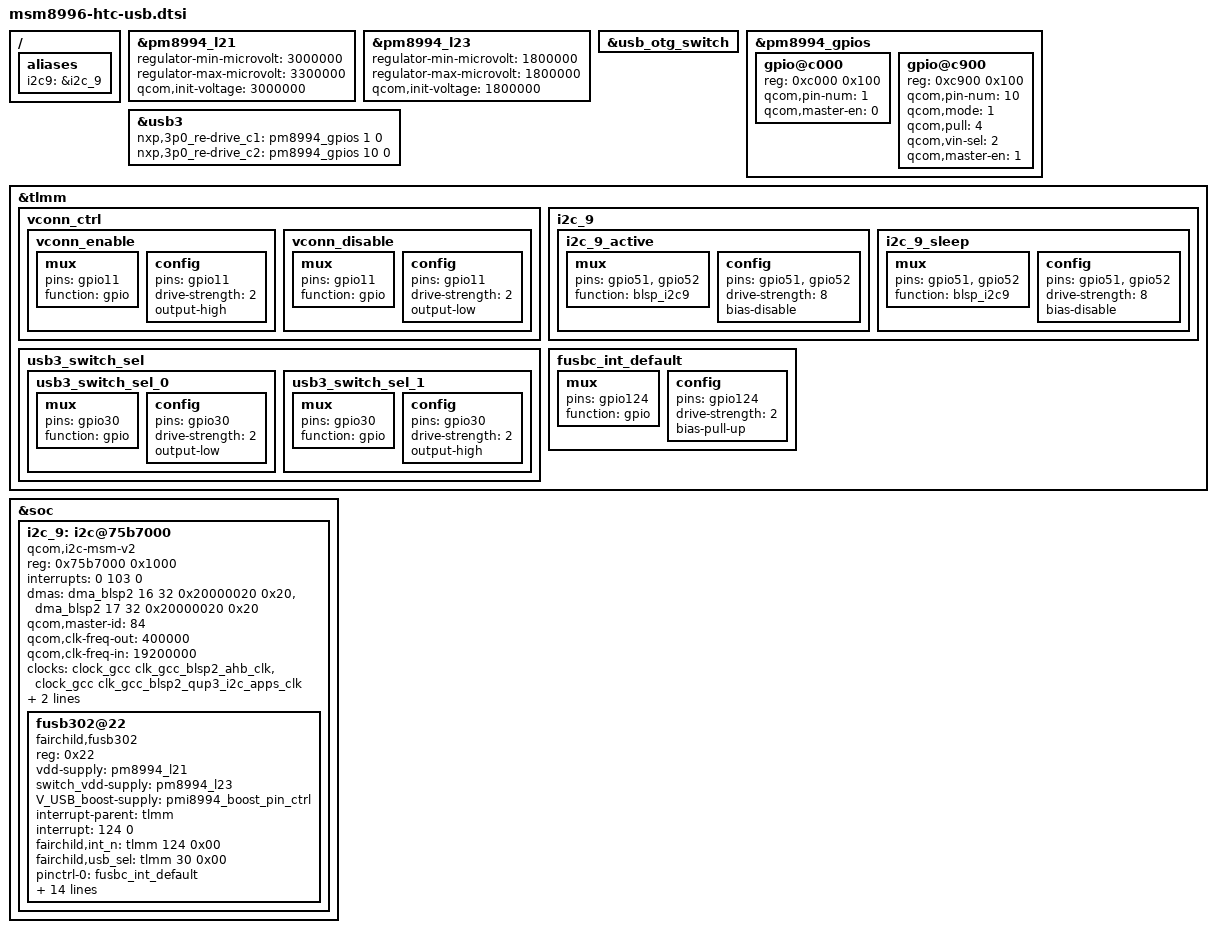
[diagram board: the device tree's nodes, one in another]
/* Copyright (c) 2016, The Linux Foundation. All rights reserved.
 *
 * This program is free software; you can redistribute it and/or modify
 * it under the terms of the GNU General Public License version 2 and
 * only version 2 as published by the Free Software Foundation.
 *
 * This program is distributed in the hope that it will be useful,
 * but WITHOUT ANY WARRANTY; without even the implied warranty of
 * MERCHANTABILITY or FITNESS FOR A PARTICULAR PURPOSE.  See the
 * GNU General Public License for more details.
 */

#include <dt-bindings/usb/typec.h>

&pm8994_l21 {
	regulator-min-microvolt = <3000000>;
	regulator-max-microvolt = <3300000>;
	qcom,init-voltage = <3000000>;
};

&pm8994_l23 {
	regulator-min-microvolt = <1800000>;
	regulator-max-microvolt = <1800000>;
	qcom,init-voltage = <1800000>;
};

&usb_otg_switch {
        status = "okay";
};

&pm8994_gpios {
	gpio@c000 {
		reg = <0xc000 0x100>;
		qcom,pin-num = <1>;
		qcom,master-en = <0>;
		status = "okay";
	};

	gpio@c900 {
		reg = <0xc900 0x100>;
		qcom,pin-num = <10>;
		qcom,mode = <1>;
		qcom,pull = <4>;
		qcom,vin-sel = <2>;
		qcom,master-en = <1>;
		status = "okay";
	};
};

&usb3 {
	nxp,3p0_re-drive_c1 = <&pm8994_gpios 1 0>;
	nxp,3p0_re-drive_c2 = <&pm8994_gpios 10 0>;
};

&tlmm {

	vconn_ctrl {
		vconn_enable: vconn_enable {
			mux {
				pins = "gpio11";
				function = "gpio";
			};

			config {
				pins = "gpio11";
				drive-strength = <2>;
				output-high;
			};
		};

		vconn_disable: vconn_disable {
			mux {
				pins = "gpio11";
				function = "gpio";
			};

			config {
				pins = "gpio11";
				drive-strength = <2>;
				output-low;
			};
		};
	};

	i2c_9 {
		i2c_9_active: i2c_9_active {
			mux {
				pins = "gpio51", "gpio52";
				function = "blsp_i2c9";
			};

			config {
				pins = "gpio51", "gpio52";
				drive-strength = <8>;
				bias-disable;
			};
		};

		i2c_9_sleep: i2c_9_sleep {
			mux {
				pins = "gpio51", "gpio52";
				function = "blsp_i2c9";
			};

			config {
				pins = "gpio51", "gpio52";
				drive-strength = <8>;
				bias-disable;
			};
		};
	};

	usb3_switch_sel {
		usb3_switch_sel_0: usb3_switch_sel_0 {
			mux {
				pins = "gpio30";
				function = "gpio";
			};

			config {
				pins = "gpio30";
				drive-strength = <2>;
				output-low;
			};
		};

		usb3_switch_sel_1: usb3_switch_sel_1 {
			mux {
				pins = "gpio30";
				function = "gpio";
			};

			config {
				pins = "gpio30";
				drive-strength = <2>;
				output-high;
			};
		};
	};

	fusbc_int_default: fusbc_int_default {
		mux {
			pins = "gpio124";
			function = "gpio";
		};

		config {
			pins = "gpio124";
			drive-strength = <2>;
			bias-pull-up;
		};
	};
};

/ {
	aliases {
		i2c9 = &i2c_9;
	};
};

&soc {
	i2c_9: i2c@75b7000 {
		compatible = "qcom,i2c-msm-v2";
		#address-cells = <1>;
		#size-cells = <0>;
		reg-names = "qup_phys_addr";
		reg = <0x75b7000 0x1000>;
		interrupt-names = "qup_irq";
		interrupts = <0 103 0>;
		dmas = <&dma_blsp2 16 32 0x20000020 0x20>,
			<&dma_blsp2 17 32 0x20000020 0x20>;
		dma-names = "tx", "rx";
		qcom,master-id = <84>;
		qcom,clk-freq-out = <400000>;
		qcom,clk-freq-in  = <19200000>;
		clock-names = "iface_clk", "core_clk";
		clocks = <&clock_gcc clk_gcc_blsp2_ahb_clk>,
			<&clock_gcc clk_gcc_blsp2_qup3_i2c_apps_clk>;
		pinctrl-names = "i2c_active", "i2c_sleep";
		pinctrl-0 = <&i2c_9_active>;
		pinctrl-1 = <&i2c_9_sleep>;

		fusb302@22 {
			compatible = "fairchild,fusb302";
			reg = <0x22>;
			vdd-supply = <&pm8994_l21>;
			switch_vdd-supply = <&pm8994_l23>;
			V_USB_boost-supply = <&pmi8994_boost_pin_ctrl>;
			status = "okay";
			interrupt-parent = <&tlmm>;
			interrupt = <124 0>;
			fairchild,int_n = <&tlmm 124 0x00>;
			fairchild,usb_sel = <&tlmm 30 0x00>;
			pinctrl-names = "default", "usb3_switch_sel_0", "usb3_switch_sel_1", "vconn_enable", "vconn_disable";
			pinctrl-0 = <&fusbc_int_default>;
			pinctrl-1 = <&usb3_switch_sel_0>;
			pinctrl-2 = <&usb3_switch_sel_1>;
			pinctrl-3 = <&vconn_enable>;
			pinctrl-4 = <&vconn_disable>;

			src-pdo = <PDO_TYPE_FIXED 5000 900 0>;		/* FIXED 5V-0.9A */
			snk-pdo = <PDO_TYPE_FIXED 5000 3000 0>,		/* FIXED 5V-3A */
				  <PDO_TYPE_FIXED 9000 2000 0>,		/* FIXED 9V-2A */
				  <PDO_TYPE_BATT 4000 10000 18000>;	/* BATT [4-10]V-18W */
			max-snk-mv = <9000>;
			max-snk-ma = <3000>;
			max-snk-mw = <18000>;
			op-snk-mw = <7600>;
			port-type = <TYPEC_PORT_DRP>;			/* TYPEC_PORT_DRP */
			default-role = <TYPEC_SINK>;			/* TYPEC_SINK */
		};
	};
};

